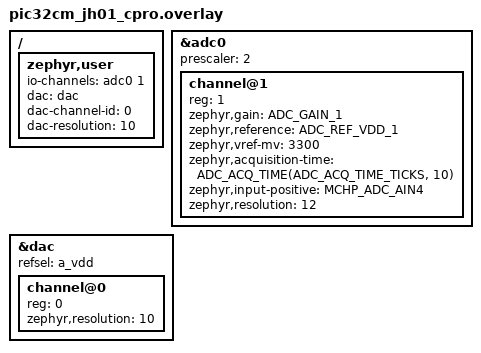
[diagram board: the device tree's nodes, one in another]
/*
 * SPDX-FileCopyrightText: Copyright (c) 2026 Microchip Technology Inc.
 *
 * SPDX-License-Identifier: Apache-2.0
 */

/* Connect the PA02 (DAC-OUT) to PA04 (ADC AIN4) for the test */

/ {
	zephyr,user {
		io-channels = <&adc0 1>;
		dac = <&dac>;
		dac-channel-id = <0>;
		dac-resolution = <10>;
	};
};

&adc0 {
	#address-cells = <1>;
	#size-cells = <0>;
	prescaler = <2>;
	status = "okay";

	channel@1 {
		reg = <1>;
		zephyr,gain = "ADC_GAIN_1";
		zephyr,reference = "ADC_REF_VDD_1";
		zephyr,vref-mv = <3300>;
		zephyr,acquisition-time = <ADC_ACQ_TIME(ADC_ACQ_TIME_TICKS, 10)>;
		zephyr,input-positive = <MCHP_ADC_AIN4>;
		zephyr,resolution = <12>;
	};
};

&dac {
	refsel = "a_vdd";
	#address-cells = <1>;
	#size-cells = <0>;
	status = "okay";

	channel@0 {
		reg = <0>;
		zephyr,resolution = <10>;
	};
};
